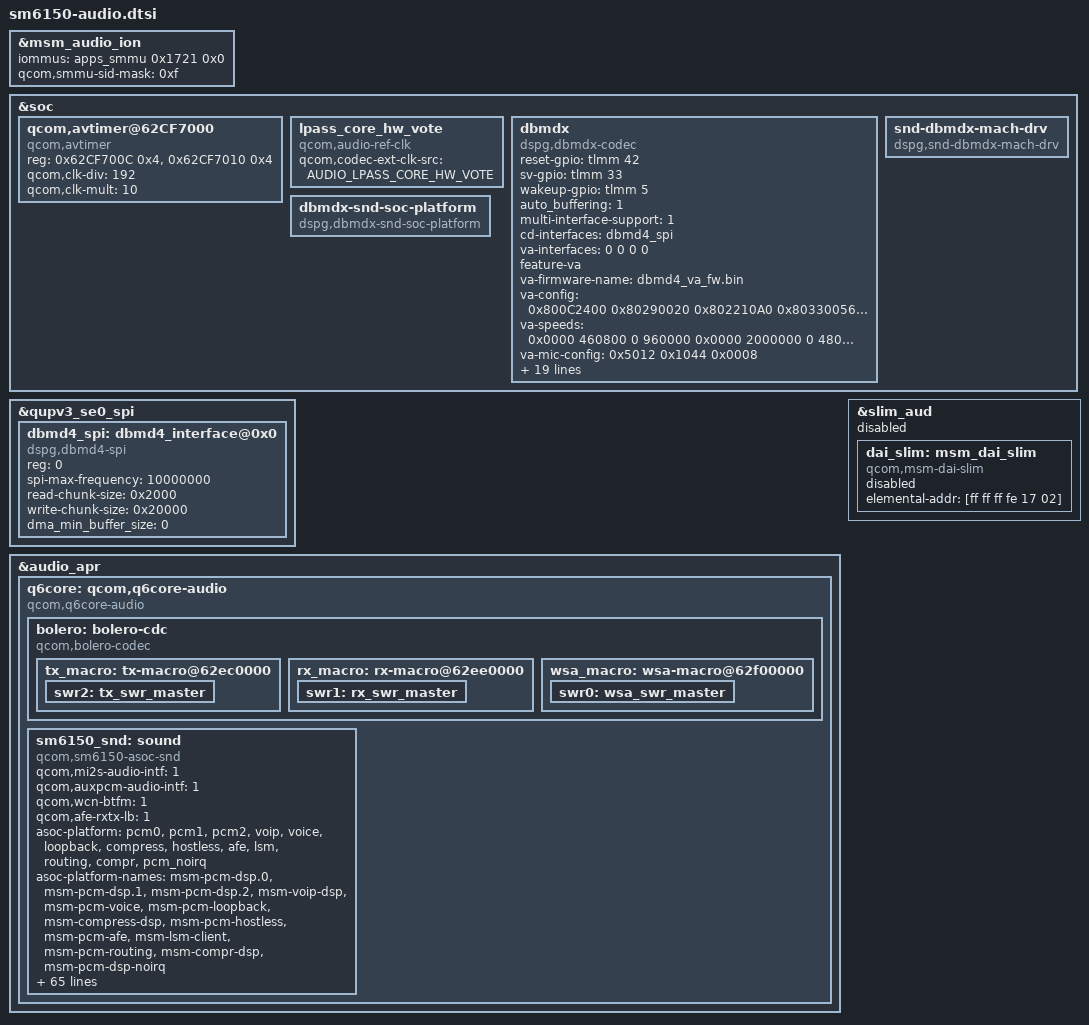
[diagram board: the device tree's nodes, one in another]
/*
 * Copyright (c) 2018-2020, The Linux Foundation. All rights reserved.
 *
 * This program is free software; you can redistribute it and/or modify
 * it under the terms of the GNU General Public License version 2 and
 * only version 2 as published by the Free Software Foundation.
 *
 * This program is distributed in the hope that it will be useful,
 * but WITHOUT ANY WARRANTY; without even the implied warranty of
 * MERCHANTABILITY or FITNESS FOR A PARTICULAR PURPOSE.  See the
 * GNU General Public License for more details.
 */

#include "msm-audio-lpass.dtsi"
#include "dt-bindings/clock/qcom,audio-ext-clk.h"

&msm_audio_ion {
	iommus = <&apps_smmu 0x1721 0x0>;
	qcom,smmu-sid-mask = /bits/ 64 <0xf>;
};

&soc {
	qcom,avtimer@62CF7000 {
		compatible = "qcom,avtimer";
		reg = <0x62CF700C 0x4>,
		      <0x62CF7010 0x4>;
		reg-names = "avtimer_lsb_addr", "avtimer_msb_addr";
		qcom,clk-div = <192>;
		qcom,clk-mult = <10>;
	};

	lpass_core_hw_vote: lpass_core_hw_vote {
		compatible = "qcom,audio-ref-clk";
		qcom,codec-ext-clk-src = <AUDIO_LPASS_CORE_HW_VOTE>;
		#clock-cells = <1>;
	};


	//#ifdef OPLUS_ARCH_EXTENDS
	dbmdx: dbmdx {
		//status = "disabled";
		compatible = "dspg,dbmdx-codec";

		reset-gpio = <&tlmm 42 0>;
		sv-gpio = <&tlmm 33 0>;
		wakeup-gpio = <&tlmm 5 0>;

		auto_buffering = <1>;
		multi-interface-support = <1>;
		cd-interfaces = <&dbmd4_spi>;
		va-interfaces = <0 0 0 0>;
		feature-va; /* enable VA */
		va-firmware-name = "dbmd4_va_fw.bin";
		va-config = <0x800C2400
			0x80290020
			0x802210A0
			0x80330056
			0x80091400
			0x80158E8E
			0x8018000A
			0x801b0020
			0x80230000
			0x801A0013
			0x80108000
			0x8aab0040
			0x805004B0
			0x805104B0
			0x80410001
			0x8060c01f
			0x8061f72b
			0x806221c0
			0x8063fb2f
			0x8064887f
			0x8065f9f1
			0x80660006
			0x80000000
			0x80000000
			0x80000000>;
		va-speeds = <0x0000 460800  0 960000
			0x0000 2000000 0 4800000
			0x0000 3000000 0 4800000>;
		va-mic-config = <0x5012 0x1044 0x0008>;
		va-mic-mode = <4>;

	//		digital_mic_digital_gain = <0x14>;
		analog_mic_analog_gain = <0x16>;
	//		analog_mic_digital_gain = <0x14>;

		master-clk-rate = <32768>;
		/* constant-clk-rate = <32768>; */
		firmware_id = <0xdbd4>;
		use_gpio_for_wakeup = <1>; /* Use wakeup gpio */
		wakeup_set_value = <0>;  /* Value to write to wakeup gpio */
		auto_detection = <1>;
		detection_buffer_channels = <0>;
		min_samples_chunk_size = <128>;
		pcm_streaming_mode = <1>;
		boot_options = <0x200>; /* Verify chip id */
		amodel_options = <0x24>;
		send_uevent_on_detection = <1>;
		send_uevent_after_buffering = <0>;
		detection_after_buffering = <0>;
		va_backlog_length = <0x780>;
		va_advanced_options = <0x1D>; /* Split Passphrase/Buf, Send det and buf events, Send event after passphrase */
		va_passphrase_margins = <0x00320640>;
		pinctrl-names = "default";
		pinctrl-0 = <&dspg_sleep_clk_default>;
	};

	dbmdx-snd-soc-platform {
		compatible = "dspg,dbmdx-snd-soc-platform";
	};

	snd-dbmdx-mach-drv {
		compatible = "dspg,snd-dbmdx-mach-drv";
	};
//#endif /* OPLUS_ARCH_EXTENDS */
};

&qupv3_se0_spi {
	status = "okay";

	dbmd4_spi:dbmd4_interface@0x0 {
		//status = "disabled";
		compatible = "dspg,dbmd4-spi";
		reg = <0>;
		spi-max-frequency = <10000000>;
		read-chunk-size  = <0x2000> ;
		write-chunk-size = <0x20000> ;
		dma_min_buffer_size = <0>;
	};

};

&audio_apr {
	q6core: qcom,q6core-audio {
		compatible = "qcom,q6core-audio";
		bolero: bolero-cdc {
			compatible = "qcom,bolero-codec";
			tx_macro: tx-macro@62ec0000 {
				swr2: tx_swr_master {
				};
			};

			rx_macro: rx-macro@62ee0000 {
				swr1: rx_swr_master {
				};
			};
			wsa_macro: wsa-macro@62f00000 {
				swr0: wsa_swr_master {
				};
			};
		};
	};
};

&q6core {
	sm6150_snd: sound {
		compatible = "qcom,sm6150-asoc-snd";
		qcom,mi2s-audio-intf = <1>;
		qcom,auxpcm-audio-intf = <1>;
		qcom,wcn-btfm = <1>;

//#ifdef OPLUS_ARCH_EXTENDS
//add for RX-to-TX AFE Loopback for AEC path
		qcom,afe-rxtx-lb = <1>;
//#endif /* OPLUS_ARCH_EXTENDS */


		asoc-platform = <&pcm0>, <&pcm1>, <&pcm2>, <&voip>, <&voice>,
				<&loopback>, <&compress>, <&hostless>,
				<&afe>, <&lsm>, <&routing>, <&compr>,
				<&pcm_noirq>;
		asoc-platform-names = "msm-pcm-dsp.0", "msm-pcm-dsp.1",
				"msm-pcm-dsp.2", "msm-voip-dsp",
				"msm-pcm-voice", "msm-pcm-loopback",
				"msm-compress-dsp", "msm-pcm-hostless",
				"msm-pcm-afe", "msm-lsm-client",
				"msm-pcm-routing", "msm-compr-dsp",
				"msm-pcm-dsp-noirq";
		asoc-cpu = <&dai_dp>,
				<&dai_mi2s0>, <&dai_mi2s1>,
				<&dai_mi2s2>, <&dai_mi2s3>,
				<&dai_mi2s4>, <&dai_pri_auxpcm>,
				<&dai_sec_auxpcm>, <&dai_tert_auxpcm>,
				<&dai_quat_auxpcm>, <&dai_quin_auxpcm>,
				<&afe_pcm_rx>, <&afe_pcm_tx>, <&afe_proxy_rx>,
				<&afe_proxy_tx>, <&incall_record_rx>,
				<&incall_record_tx>, <&incall_music_rx>,
				<&incall_music_2_rx>,
				<&sb_7_rx>, <&sb_7_tx>, <&sb_8_tx>, <&sb_8_rx>,
				<&proxy_rx>, <&proxy_tx>,
				<&usb_audio_rx>, <&usb_audio_tx>,
				<&dai_pri_tdm_rx_0>, <&dai_pri_tdm_tx_0>,
				<&dai_sec_tdm_rx_0>, <&dai_sec_tdm_tx_0>,
				<&dai_tert_tdm_rx_0>, <&dai_tert_tdm_tx_0>,
				<&dai_quat_tdm_rx_0>, <&dai_quat_tdm_tx_0>,
				<&dai_quin_tdm_rx_0>, <&dai_quin_tdm_tx_0>,
				<&wsa_cdc_dma_0_rx>, <&wsa_cdc_dma_0_tx>,
				<&wsa_cdc_dma_1_rx>, <&wsa_cdc_dma_1_tx>,
				<&wsa_cdc_dma_2_tx>,
				<&rx_cdc_dma_0_rx>, <&tx_cdc_dma_0_tx>,
				<&rx_cdc_dma_1_rx>, <&tx_cdc_dma_1_tx>,
				<&rx_cdc_dma_2_rx>, <&tx_cdc_dma_2_tx>,
				<&rx_cdc_dma_3_rx>, <&tx_cdc_dma_3_tx>,
				<&rx_cdc_dma_4_rx>, <&tx_cdc_dma_4_tx>,
				<&rx_cdc_dma_5_rx>, <&tx_cdc_dma_5_tx>,

//#ifdef OPLUS_ARCH_EXTENDS
//add for RX-to-TX AFE Loopback for AEC path
				<&rx_cdc_dma_6_rx>, <&rx_cdc_dma_7_rx>,
				<&afe_loopback_tx>;
//#else /* OPLUS_ARCH_EXTENDS */
//				<&rx_cdc_dma_6_rx>, <&rx_cdc_dma_7_rx>;
//#endif /* OPLUS_ARCH_EXTENDS */

		asoc-cpu-names = "msm-dai-q6-dp.24608",
				"msm-dai-q6-mi2s.0", "msm-dai-q6-mi2s.1",
				"msm-dai-q6-mi2s.2", "msm-dai-q6-mi2s.3",
				"msm-dai-q6-mi2s.4", "msm-dai-q6-auxpcm.1",
				"msm-dai-q6-auxpcm.2", "msm-dai-q6-auxpcm.3",
				"msm-dai-q6-auxpcm.4", "msm-dai-q6-auxpcm.5",
				"msm-dai-q6-dev.224",
				"msm-dai-q6-dev.225", "msm-dai-q6-dev.241",
				"msm-dai-q6-dev.240", "msm-dai-q6-dev.32771",
				"msm-dai-q6-dev.32772", "msm-dai-q6-dev.32773",
				"msm-dai-q6-dev.32770", "msm-dai-q6-dev.16398",
				"msm-dai-q6-dev.16399", "msm-dai-q6-dev.16401",
				"msm-dai-q6-dev.16400",
				"msm-dai-q6-dev.8194", "msm-dai-q6-dev.8195",
				"msm-dai-q6-dev.28672", "msm-dai-q6-dev.28673",
				"msm-dai-q6-tdm.36864", "msm-dai-q6-tdm.36865",
				"msm-dai-q6-tdm.36880", "msm-dai-q6-tdm.36881",
				"msm-dai-q6-tdm.36896", "msm-dai-q6-tdm.36897",
				"msm-dai-q6-tdm.36912", "msm-dai-q6-tdm.36913",
				"msm-dai-q6-tdm.36928", "msm-dai-q6-tdm.36929",
				"msm-dai-cdc-dma-dev.45056",
				"msm-dai-cdc-dma-dev.45057",
				"msm-dai-cdc-dma-dev.45058",
				"msm-dai-cdc-dma-dev.45059",
				"msm-dai-cdc-dma-dev.45061",
				"msm-dai-cdc-dma-dev.45104",
				"msm-dai-cdc-dma-dev.45105",
				"msm-dai-cdc-dma-dev.45106",
				"msm-dai-cdc-dma-dev.45107",
				"msm-dai-cdc-dma-dev.45108",
				"msm-dai-cdc-dma-dev.45109",
				"msm-dai-cdc-dma-dev.45110",
				"msm-dai-cdc-dma-dev.45111",
				"msm-dai-cdc-dma-dev.45112",
				"msm-dai-cdc-dma-dev.45113",
				"msm-dai-cdc-dma-dev.45114",
				"msm-dai-cdc-dma-dev.45115",
				"msm-dai-cdc-dma-dev.45116",

//#ifdef OPLUS_ARCH_EXTENDS
//add for RX-to-TX AFE Loopback for AEC path
				"msm-dai-cdc-dma-dev.45118",
				"msm-dai-q6-dev.24577";
//#else /* OPLUS_ARCH_EXTENDS */
//				"msm-dai-cdc-dma-dev.45118";
//#endif /* OPLUS_ARCH_EXTENDS */
		fsa4480-i2c-handle = <&fsa4480>;
	};
};

&slim_aud {
	status = "disabled";
	dai_slim: msm_dai_slim {
		status = "disabled";
		compatible = "qcom,msm-dai-slim";
		elemental-addr = [ff ff ff fe 17 02];
	};
};
